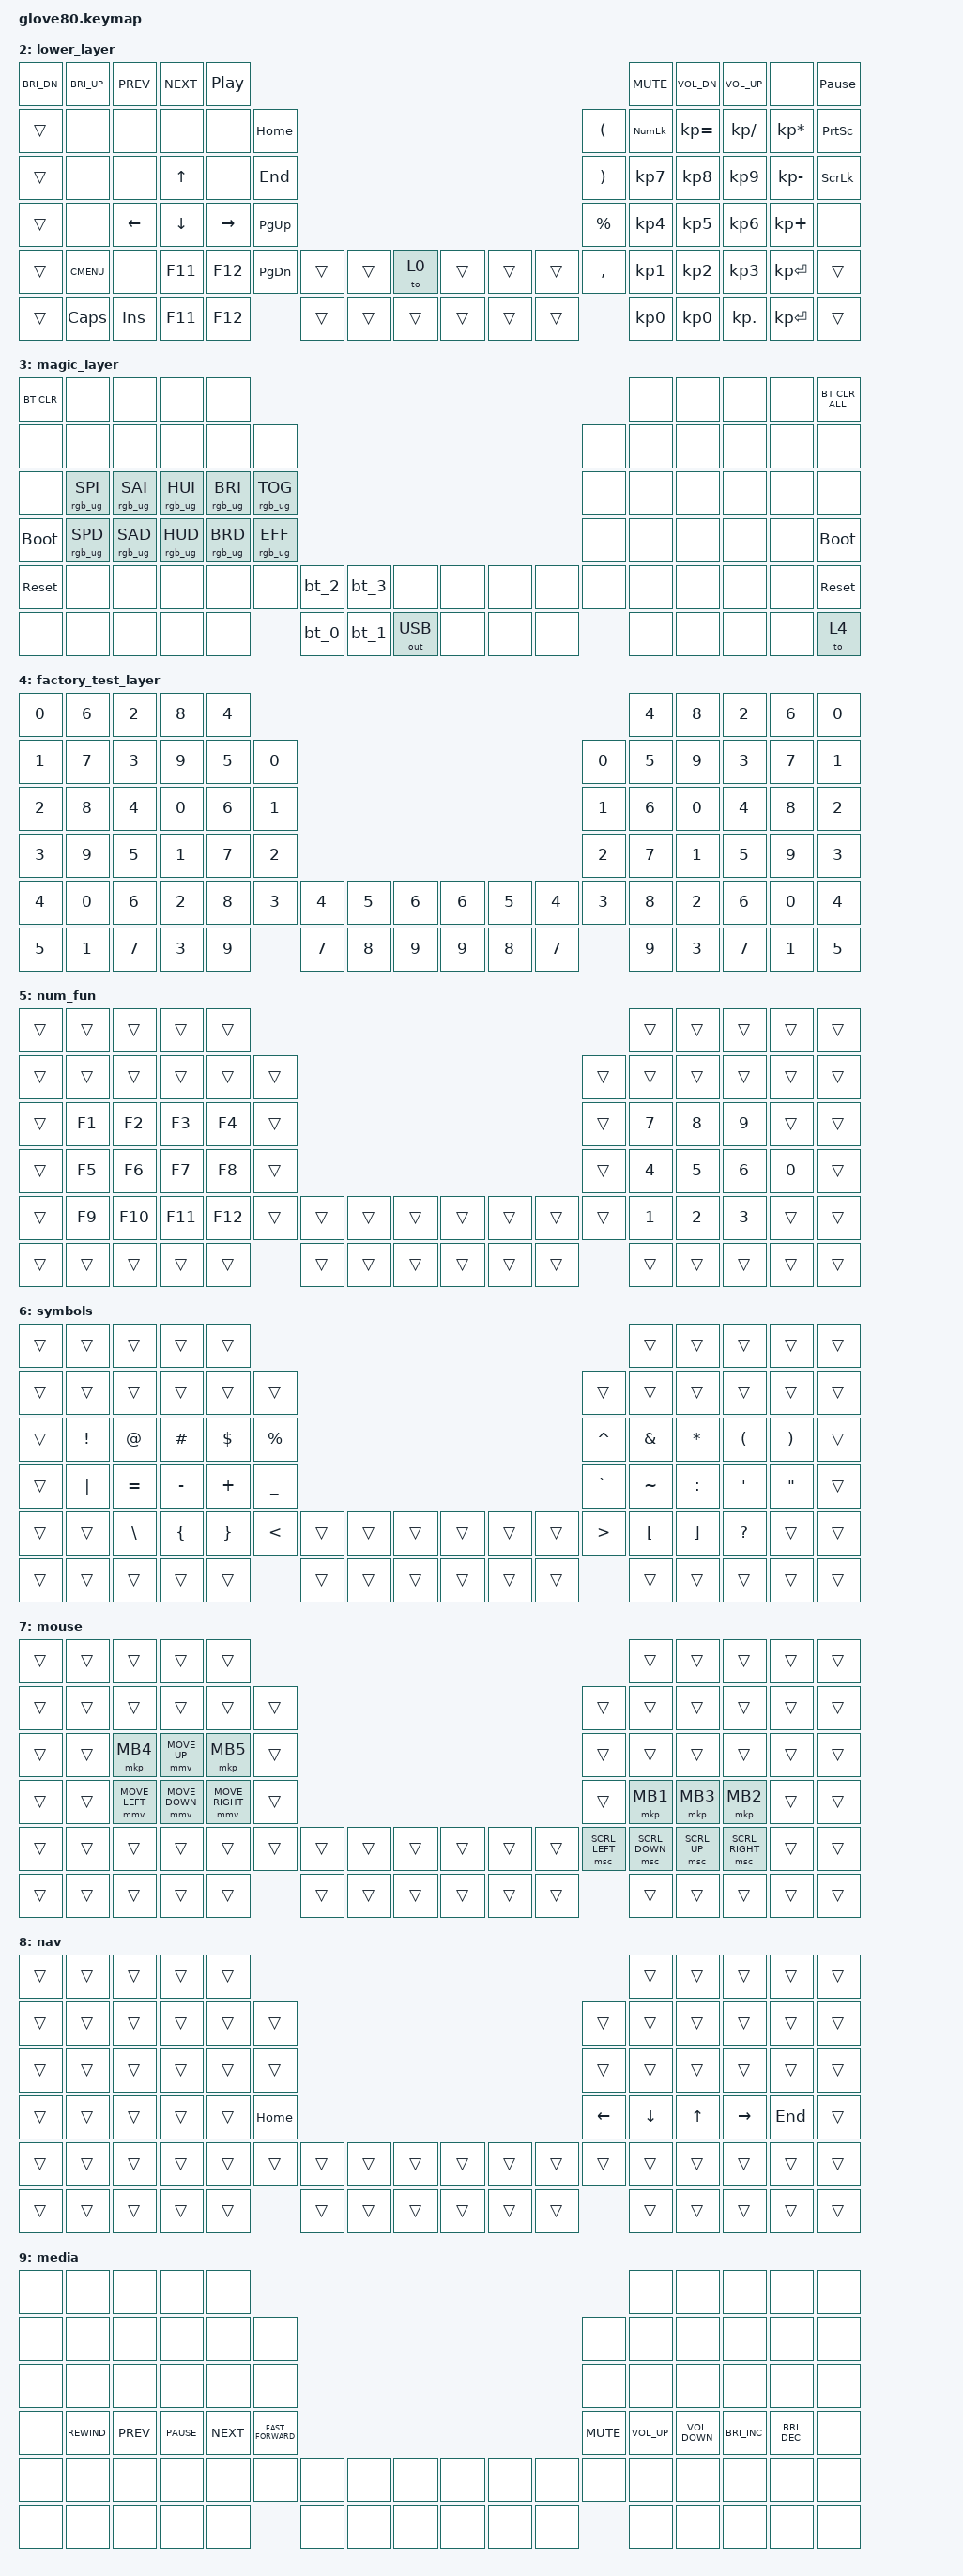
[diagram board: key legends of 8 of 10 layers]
/*
 * Copyright (c) 2020 The ZMK Contributors
 *
 * SPDX-License-Identifier: MIT
 */

#include <behaviors.dtsi>
#include <dt-bindings/zmk/bt.h>
#include <dt-bindings/zmk/keys.h>
#include <dt-bindings/zmk/outputs.h>
#include <dt-bindings/zmk/pointing.h>
#include <dt-bindings/zmk/rgb.h>

#define HYPER LC(LS(LG(LALT)))

// layers

#define DEFAULT 0
#define LOWER 1
#define MAGIC 2
#define FACTORY_TEST 3

/ {
    behaviors {
        // For the "layer" key, it'd nice to be able to use it as either a shift or a toggle.
        // Configure it as a tap dance, so the first tap (or hold) is a &mo and the second tap is a &to

        layer_td: tap_dance_0 {
            compatible = "zmk,behavior-tap-dance";
            label = "LAYER_TAP_DANCE";
            #binding-cells = <0>;
            tapping-term-ms = <200>;
            bindings = <&mo 2>, <&to 2>;
        };

        magic: magic_hold_tap {
            compatible = "zmk,behavior-hold-tap";
            label = "MAGIC_HOLD_TAP";
            #binding-cells = <2>;
            flavor = "tap-preferred";
            tapping-term-ms = <200>;
            bindings = <&mo>, <&rgb_ug_status_macro>;
        };

        balanced_mod_tap: balanced_mod_tap {
            compatible = "zmk,behavior-hold-tap";
            label = "BALANCED_MOD_TAP";
            bindings = <&kp>, <&kp>;

            #binding-cells = <2>;
            tapping-term-ms = <200>;
            quick-tap-ms = <200>;
            flavor = "tap-preferred";
            hold-while-undecided-linger;
        };

        tap_layer: tap_layer {
            compatible = "zmk,behavior-hold-tap";
            label = "TAP_LAYER";
            bindings = <&mo>, <&kp>;

            #binding-cells = <2>;
            flavor = "tap-preferred";
            tapping-term-ms = <200>;
            quick-tap-ms = <200>;
            hold-while-undecided-linger;
        };
    };

    macros {
        rgb_ug_status_macro: rgb_ug_status_macro_0 {
            label = "RGB_UG_STATUS";
            compatible = "zmk,behavior-macro";
            #binding-cells = <0>;
            bindings = <&rgb_ug RGB_STATUS>;
        };

        bt_0: bt_profile_macro_0 {
            label = "BT_0";
            compatible = "zmk,behavior-macro";
            #binding-cells = <0>;
            bindings = <&out OUT_BLE &bt BT_SEL 0>;
        };

        bt_1: bt_profile_macro_1 {
            label = "BT_1";
            compatible = "zmk,behavior-macro";
            #binding-cells = <0>;
            bindings = <&out OUT_BLE &bt BT_SEL 1>;
        };

        bt_2: bt_profile_macro_2 {
            label = "BT_2";
            compatible = "zmk,behavior-macro";
            #binding-cells = <0>;
            bindings = <&out OUT_BLE &bt BT_SEL 2>;
        };

        bt_3: bt_profile_macro_3 {
            label = "BT_3";
            compatible = "zmk,behavior-macro";
            #binding-cells = <0>;
            bindings = <&out OUT_BLE &bt BT_SEL 3>;
        };
    };

    combos {
        compatible = "zmk,combos";

        enter {
            bindings = <&kp ENTER>;
            key-positions = <36 37>;
        };

        tab {
            bindings = <&kp TAB>;
            key-positions = <37 38>;
        };

        escape {
            bindings = <&kp ESCAPE>;
            key-positions = <41 42>;
        };

        backspace {
            bindings = <&kp BACKSPACE>;
            key-positions = <43 42>;
        };
    };

    keymap {
        compatible = "zmk,keymap";

        base {
            // ---------------------------------------------------------------------------------------------------------------------------------
            // |  F1   |  F2 |  F3 |  F4  |  F5  |                                                               |  F6   |  F7   |  F8  |   F9  |  F10 |
            // |  =    |  1  |  2  |  3   |  4   |  5   |                                                 |  6   |   7   |   8   |  9   |   0   |   -  |
            // |  TAB  |  Q  |  W  |  E   |  R   |  T   |                                                 |  Y   |   U   |   I   |  O   |   P   |   \  |
            // |  ESC  |  A  |  S  |  D   |  F   |  G   |                                                 |  H   |   J   |   K   |  L   |   ;   |   '  |
            // |   `   |  Z  |  X  |  C   |  V   |  B   | LSHFT | LCTRL | LOWER | | LGUI  | RCTRL | RSHFT |  N   |   M   |   ,   |  .   |   /   | PGUP |
            // | MAGIC | HOME| END | LEFT | RIGHT|      | BSPC  | DEL   | LALT  | | RALT  | RET   | SPACE |      |  UP   | DOWN  |  [   |   ]   | PGDN |

            bindings = <
&kp F1      &kp F2                     &kp F3                        &kp F4                            &kp F5                                                                                                                                                                                  &kp F6                           &kp F7                            &kp F8                        &kp F9                             &kp F10
&kp EQUAL   &kp N1                     &kp N2                        &kp N3                            &kp N4                          &kp N5                                                                                                                                  &kp N6          &kp N7                           &kp N8                            &kp N9                        &kp N0                             &kp MINUS
&kp DELETE  &kp Q                      &kp W                         &kp E                             &kp R                           &kp T                                                                                                                                   &kp Y           &kp U                            &kp I                             &kp O                         &kp P                              &kp BSLH
&kp ESC     &balanced_mod_tap LMETA A  &balanced_mod_tap LEFT_ALT S  &balanced_mod_tap LEFT_CONTROL D  &balanced_mod_tap LEFT_SHIFT F  &tap_layer 5 G                                                                                                                          &tap_layer 5 H  &balanced_mod_tap RIGHT_SHIFT J  &balanced_mod_tap LEFT_CONTROL K  &balanced_mod_tap LEFT_ALT L  &balanced_mod_tap RIGHT_META SEMI  &kp SQT
&kp GRAVE   &tap_layer 9 Z             &kp X                         &kp C                             &kp V                           &kp B           &kp LA(LC(LSHFT))   &kp LS(LA(LG(LCTRL)))  &layer_td        &to 1        &kp LA(LS(LG(LCTRL)))  &kp LA(LC(LEFT_SHIFT))  &kp N           &kp M                            &kp COMMA                         &kp DOT                       &tap_layer 9 SLASH                 &kp PG_UP
&magic 3 0  &kp K_UNDO                 &kp K_CUT                     &kp K_COPY                        &kp K_PASTE                                     &tap_layer 6 SPACE  &tap_layer 8 TAB       &kp LC(LS(TAB))  &kp LC(TAB)  &tap_layer 7 ENTER     &tap_layer 6 BACKSPACE                  &kp LEFT                         &kp DOWN                          &kp UP_ARROW                  &kp RIGHT                          &kp PG_DN
            >;
        };

        mac_base {
            bindings = <
&kp F1      &kp F2                            &kp F3                        &kp F4                         &kp F5                                                                                                                                                                                  &kp F6                           &kp F7                         &kp F8                        &kp F9                               &kp F10
&kp EQUAL   &kp N1                            &kp N2                        &kp N3                         &kp N4                          &kp N5                                                                                                                                  &kp N6          &kp N7                           &kp N8                         &kp N9                        &kp N0                               &kp MINUS
&kp DELETE  &kp Q                             &kp W                         &kp E                          &kp R                           &kp T                                                                                                                                   &kp Y           &kp U                            &kp I                          &kp O                         &kp P                                &kp BSLH
&kp ESC     &balanced_mod_tap LEFT_CONTROL A  &balanced_mod_tap LEFT_ALT S  &balanced_mod_tap LEFT_META D  &balanced_mod_tap LEFT_SHIFT F  &tap_layer 5 G                                                                                                                          &tap_layer 5 H  &balanced_mod_tap RIGHT_SHIFT J  &balanced_mod_tap LEFT_META K  &balanced_mod_tap LEFT_ALT L  &balanced_mod_tap LEFT_CONTROL SEMI  &kp SQT
&kp GRAVE   &tap_layer 9 Z                    &kp X                         &kp C                          &kp V                           &kp B           &kp LA(LC(LSHFT))   &kp LS(LA(LG(LCTRL)))  &layer_td        &to 0        &kp LA(LS(LG(LCTRL)))  &kp LA(LC(LEFT_SHIFT))  &kp N           &kp M                            &kp COMMA                      &kp DOT                       &tap_layer 9 SLASH                   &kp PG_UP
&magic 3 0  &kp K_UNDO                        &kp K_CUT                     &kp K_COPY                     &kp K_PASTE                                     &tap_layer 6 SPACE  &tap_layer 8 TAB       &kp LC(LS(TAB))  &kp LC(TAB)  &tap_layer 7 ENTER     &tap_layer 6 BACKSPACE                  &kp LEFT                         &kp DOWN                       &kp UP_ARROW                  &kp RIGHT                            &kp PG_DN
            >;
        };

        lower_layer {
            bindings = <
&kp C_BRI_DN  &kp C_BRI_UP  &kp C_PREV  &kp C_NEXT  &kp C_PP                                                                         &kp C_MUTE  &kp C_VOL_DN  &kp C_VOL_UP   &none            &kp PAUSE_BREAK
&trans        &none         &none       &none       &none      &kp HOME                                                   &kp LPAR   &kp KP_NUM  &kp KP_EQUAL  &kp KP_DIVIDE  &kp KP_MULTIPLY  &kp PSCRN
&trans        &none         &none       &kp UP      &none      &kp END                                                    &kp RPAR   &kp KP_N7   &kp KP_N8     &kp KP_N9      &kp KP_MINUS     &kp SLCK
&trans        &none         &kp LEFT    &kp DOWN    &kp RIGHT  &kp PG_UP                                                  &kp PRCNT  &kp KP_N4   &kp KP_N5     &kp KP_N6      &kp KP_PLUS      &none
&trans        &kp K_CMENU   &none       &kp F11     &kp F12    &kp PG_DN  &trans  &trans  &to 0   &trans  &trans  &trans  &kp COMMA  &kp KP_N1   &kp KP_N2     &kp KP_N3      &kp KP_ENTER     &trans
&trans        &kp CAPS      &kp INS     &kp F11     &kp F12               &trans  &trans  &trans  &trans  &trans  &trans             &kp KP_N0   &kp KP_N0     &kp KP_DOT     &kp KP_ENTER     &trans
            >;
        };

        magic_layer {
            bindings = <
&bt BT_CLR   &none            &none            &none            &none                                                                                     &none  &none  &none  &none  &bt BT_CLR_ALL
&none        &none            &none            &none            &none            &none                                                             &none  &none  &none  &none  &none  &none
&none        &rgb_ug RGB_SPI  &rgb_ug RGB_SAI  &rgb_ug RGB_HUI  &rgb_ug RGB_BRI  &rgb_ug RGB_TOG                                                   &none  &none  &none  &none  &none  &none
&bootloader  &rgb_ug RGB_SPD  &rgb_ug RGB_SAD  &rgb_ug RGB_HUD  &rgb_ug RGB_BRD  &rgb_ug RGB_EFF                                                   &none  &none  &none  &none  &none  &bootloader
&sys_reset   &none            &none            &none            &none            &none            &bt_2  &bt_3  &none         &none  &none  &none  &none  &none  &none  &none  &none  &sys_reset
&none        &none            &none            &none            &none                             &bt_0  &bt_1  &out OUT_USB  &none  &none  &none         &none  &none  &none  &none  &to 4
            >;
        };

        factory_test_layer {
            bindings = <
&kp N0  &kp N6  &kp N2  &kp N8  &kp N4                                                                  &kp N4  &kp N8  &kp N2  &kp N6  &kp N0
&kp N1  &kp N7  &kp N3  &kp N9  &kp N5  &kp N0                                                  &kp N0  &kp N5  &kp N9  &kp N3  &kp N7  &kp N1
&kp N2  &kp N8  &kp N4  &kp N0  &kp N6  &kp N1                                                  &kp N1  &kp N6  &kp N0  &kp N4  &kp N8  &kp N2
&kp N3  &kp N9  &kp N5  &kp N1  &kp N7  &kp N2                                                  &kp N2  &kp N7  &kp N1  &kp N5  &kp N9  &kp N3
&kp N4  &kp N0  &kp N6  &kp N2  &kp N8  &kp N3  &kp N4  &kp N5  &kp N6  &kp N6  &kp N5  &kp N4  &kp N3  &kp N8  &kp N2  &kp N6  &kp N0  &kp N4
&kp N5  &kp N1  &kp N7  &kp N3  &kp N9          &kp N7  &kp N8  &kp N9  &kp N9  &kp N8  &kp N7          &kp N9  &kp N3  &kp N7  &kp N1  &kp N5
            >;
        };

        num_fun {
            bindings = <
&trans  &trans  &trans   &trans   &trans                                                                   &trans        &trans        &trans        &trans  &trans
&trans  &trans  &trans   &trans   &trans   &trans                                                  &trans  &trans        &trans        &trans        &trans  &trans
&trans  &kp F1  &kp F2   &kp F3   &kp F4   &trans                                                  &trans  &kp N7        &kp N8        &kp N9        &trans  &trans
&trans  &kp F5  &kp F6   &kp F7   &kp F8   &trans                                                  &trans  &kp NUMBER_4  &kp N5        &kp NUMBER_6  &kp N0  &trans
&trans  &kp F9  &kp F10  &kp F11  &kp F12  &trans  &trans  &trans  &trans  &trans  &trans  &trans  &trans  &kp NUMBER_1  &kp NUMBER_2  &kp NUMBER_3  &trans  &trans
&trans  &trans  &trans   &trans   &trans           &trans  &trans  &trans  &trans  &trans  &trans          &trans        &trans        &trans        &trans  &trans
            >;
        };

        symbols {
            bindings = <
&trans  &trans           &trans         &trans          &trans                                                                                            &trans            &trans             &trans                &trans                 &trans
&trans  &trans           &trans         &trans          &trans           &trans                                                         &trans            &trans            &trans             &trans                &trans                 &trans
&trans  &kp EXCLAMATION  &kp AT_SIGN    &kp HASH        &kp DOLLAR       &kp PERCENT                                                    &kp CARET         &kp AMPERSAND     &kp ASTERISK       &kp LEFT_PARENTHESIS  &kp RIGHT_PARENTHESIS  &trans
&trans  &kp PIPE         &kp EQUAL      &kp MINUS       &kp PLUS         &kp UNDER                                                      &kp GRAVE         &kp TILDE         &kp COLON          &kp SINGLE_QUOTE      &kp DOUBLE_QUOTES      &trans
&trans  &trans           &kp BACKSLASH  &kp LEFT_BRACE  &kp RIGHT_BRACE  &kp LESS_THAN  &trans  &trans  &trans  &trans  &trans  &trans  &kp GREATER_THAN  &kp LEFT_BRACKET  &kp RIGHT_BRACKET  &kp QUESTION          &trans                 &trans
&trans  &trans           &trans         &trans          &trans                          &trans  &trans  &trans  &trans  &trans  &trans                    &trans            &trans             &trans                &trans                 &trans
            >;
        };

        mouse {
            bindings = <
&trans  &trans  &trans          &trans          &trans                                                                                   &trans          &trans        &trans           &trans  &trans
&trans  &trans  &trans          &trans          &trans           &trans                                                  &trans          &trans          &trans        &trans           &trans  &trans
&trans  &trans  &mkp MB4        &mmv MOVE_UP    &mkp MB5         &trans                                                  &trans          &trans          &trans        &trans           &trans  &trans
&trans  &trans  &mmv MOVE_LEFT  &mmv MOVE_DOWN  &mmv MOVE_RIGHT  &trans                                                  &trans          &mkp MB1        &mkp MB3      &mkp MB2         &trans  &trans
&trans  &trans  &trans          &trans          &trans           &trans  &trans  &trans  &trans  &trans  &trans  &trans  &msc SCRL_LEFT  &msc SCRL_DOWN  &msc SCRL_UP  &msc SCRL_RIGHT  &trans  &trans
&trans  &trans  &trans          &trans          &trans                   &trans  &trans  &trans  &trans  &trans  &trans                  &trans          &trans        &trans           &trans  &trans
            >;
        };

        nav {
            bindings = <
&trans  &trans  &trans  &trans  &trans                                                                      &trans    &trans        &trans     &trans   &trans
&trans  &trans  &trans  &trans  &trans  &trans                                                    &trans    &trans    &trans        &trans     &trans   &trans
&trans  &trans  &trans  &trans  &trans  &trans                                                    &trans    &trans    &trans        &trans     &trans   &trans
&trans  &trans  &trans  &trans  &trans  &kp HOME                                                  &kp LEFT  &kp DOWN  &kp UP_ARROW  &kp RIGHT  &kp END  &trans
&trans  &trans  &trans  &trans  &trans  &trans    &trans  &trans  &trans  &trans  &trans  &trans  &trans    &trans    &trans        &trans     &trans   &trans
&trans  &trans  &trans  &trans  &trans            &trans  &trans  &trans  &trans  &trans  &trans            &trans    &trans        &trans     &trans   &trans
            >;
        };

        media {
            bindings = <
&none  &none         &none       &none        &none                                                                                 &none            &none              &none                 &none                 &none
&none  &none         &none       &none        &none       &none                                                         &none       &none            &none              &none                 &none                 &none
&none  &none         &none       &none        &none       &none                                                         &none       &none            &none              &none                 &none                 &none
&none  &kp C_REWIND  &kp C_PREV  &kp C_PAUSE  &kp C_NEXT  &kp C_FAST_FORWARD                                            &kp K_MUTE  &kp C_VOLUME_UP  &kp C_VOLUME_DOWN  &kp C_BRIGHTNESS_INC  &kp C_BRIGHTNESS_DEC  &none
&none  &none         &none       &none        &none       &none               &none  &none  &none  &none  &none  &none  &none       &none            &none              &none                 &none                 &none
&none  &none         &none       &none        &none                           &none  &none  &none  &none  &none  &none              &none            &none              &none                 &none                 &none
            >;
        };
    };
};
